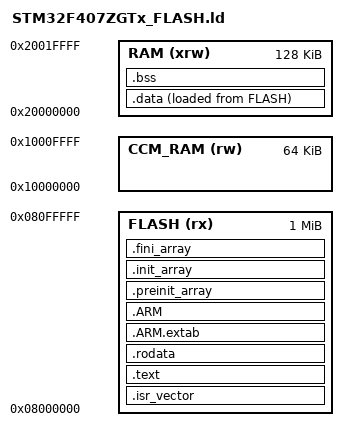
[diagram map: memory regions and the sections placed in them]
/*
 * STM32F407ZGT6 Linker Script for arm-none-eabi-gcc
 * Flash: 1MB @ 0x08000000
 * SRAM:  128KB @ 0x20000000
 */

/* Entry point */
ENTRY(Reset_Handler)

/* Highest address of the user mode stack */
_estack = ORIGIN(RAM) + LENGTH(RAM);

/* Generate a link error if heap and stack don't fit into RAM */
_Min_Heap_Size = 0x200;      /* 2KB heap */
_Min_Stack_Size = 0x400;     /* 4KB stack */

MEMORY
{
  FLASH (rx)      : ORIGIN = 0x08000000, LENGTH = 1024K
  RAM   (xrw)     : ORIGIN = 0x20000000, LENGTH = 128K
  CCM_RAM (rw)    : ORIGIN = 0x10000000, LENGTH = 64K
}

/* Entry point */
ENTRY(Reset_Handler)

SECTIONS
{
  /* The startup code goes first into FLASH */
  .isr_vector :
  {
    . = ALIGN(4);
    KEEP(*(.isr_vector))
    . = ALIGN(4);
  } >FLASH

  /* Program code */
  .text :
  {
    . = ALIGN(4);
    *(.text)
    *(.text*)
    *(.glue_7)
    *(.glue_7t)
    KEEP(*(.init))
    KEEP(*(.fini))
    . = ALIGN(4);
    _etext = .;
  } >FLASH

  /* Read-only data */
  .rodata :
  {
    . = ALIGN(4);
    *(.rodata)
    *(.rodata*)
    . = ALIGN(4);
  } >FLASH

  /* ARM exception handling tables */
  .ARM.extab   : { *(.ARM.extab* .gnu.linkonce.armextab.*) } >FLASH
  .ARM :
  {
    __exidx_start = .;
    *(.ARM.exidx*)
    __exidx_end = .;
  } >FLASH

  /* Preinit and init arrays */
  .preinit_array :
  {
    PROVIDE_HIDDEN(__preinit_array_start = .);
    KEEP(*(.preinit_array*))
    PROVIDE_HIDDEN(__preinit_array_end = .);
  } >FLASH

  .init_array :
  {
    PROVIDE_HIDDEN(__init_array_start = .);
    KEEP(*(SORT(.init_array.*)))
    KEEP(*(.init_array*))
    PROVIDE_HIDDEN(__init_array_end = .);
  } >FLASH

  .fini_array :
  {
    PROVIDE_HIDDEN(__fini_array_start = .);
    KEEP(*(SORT(.fini_array.*)))
    KEEP(*(.fini_array*))
    PROVIDE_HIDDEN(__fini_array_end = .);
  } >FLASH

  /* Used by startup_stm32f407xx.c to copy data and zero BSS */
  _sidata = LOADADDR(.data);

  .data :
  {
    . = ALIGN(4);
    _sdata = .;
    *(.data)
    *(.data*)
    . = ALIGN(4);
    _edata = .;
  } >RAM AT> FLASH

  /* BSS */
  .bss :
  {
    . = ALIGN(4);
    _sbss = .;
    __bss_start__ = _sbss;
    *(.bss)
    *(.bss*)
    *(COMMON)
    . = ALIGN(4);
    _ebss = .;
    __bss_end__ = _ebss;
  } >RAM

  PROVIDE(end = .);
  PROVIDE(_end = .);

  /* Remove debug info from the normal build output */
  /DISCARD/ :
  {
    *(.ARM.attributes)
  }
}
